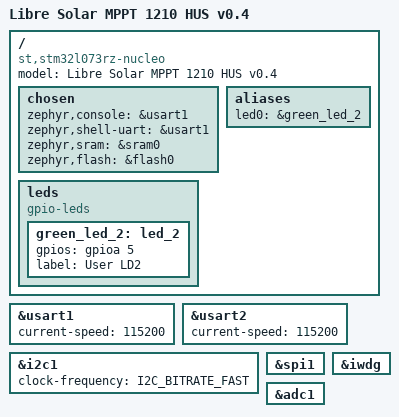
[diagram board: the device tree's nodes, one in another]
/*
 * Copyright (c) 2018 Ilya Tagunov <tagunil@gmail.com>
 *
 * SPDX-License-Identifier: Apache-2.0
 */

/dts-v1/;
#include <st/l0/stm32l073Xz.dtsi>

/ {
	model = "Libre Solar MPPT 1210 HUS v0.4";
	compatible = "st,stm32l073rz-nucleo", "st,stm32l073";

	chosen {
		zephyr,console = &usart1;
		zephyr,shell-uart = &usart1;
		zephyr,sram = &sram0;
		zephyr,flash = &flash0;
	};

	leds {
		compatible = "gpio-leds";
		green_led_2: led_2 {
			gpios = <&gpioa 5 GPIO_INT_ACTIVE_HIGH>;
			label = "User LD2";
		};
	};

	aliases {
		led0 = &green_led_2;
	};
};

&usart1 {
	current-speed = <115200>;
	status = "okay";
};

&usart2 {
	current-speed = <115200>;
	status = "okay";
};

arduino_i2c: &i2c1 {
	status = "okay";
	clock-frequency = <I2C_BITRATE_FAST>;
};

arduino_spi: &spi1 {
	status = "okay";
};

&iwdg {
	status = "okay";
};

&adc1 {
	status = "okay";
};
